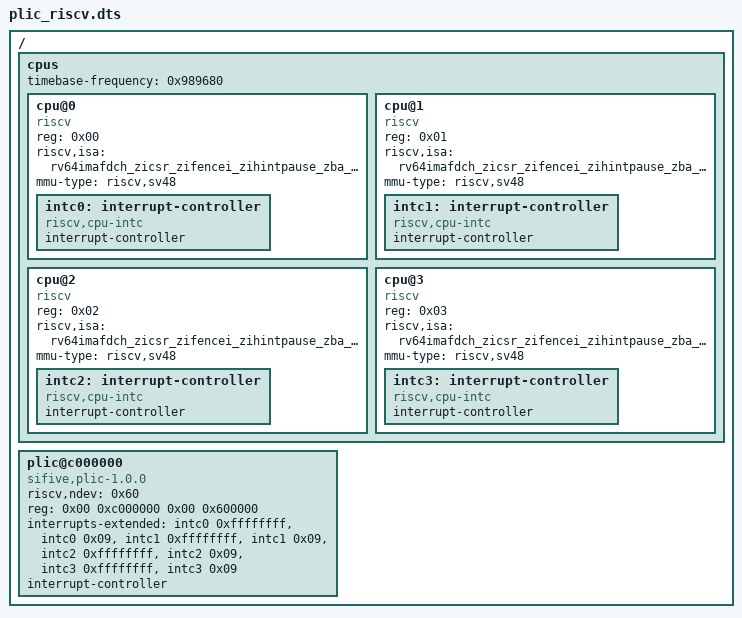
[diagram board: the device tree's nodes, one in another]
// Copyright 2024 The Fuchsia Authors. All rights reserved.
// Use of this source code is governed by a BSD-style license that can be
// found in the LICENSE file.

/dts-v1/;

/ {
    #address-cells = <0x02>;
    #size-cells = <0x02>;

    cpus {
        #address-cells = <0x01>;
        #size-cells = <0x00>;
        timebase-frequency = <0x989680>;

        cpu@0 {
            device_type = "cpu";
            reg = <0x00>;
            compatible = "riscv";
            riscv,isa = "rv64imafdch_zicsr_zifencei_zihintpause_zba_zbb_zbc_zbs_sstc";
            mmu-type = "riscv,sv48";

            intc0: interrupt-controller {
                #address-cells = <0x01>;
                #interrupt-cells = <0x01>;
                interrupt-controller;
                compatible = "riscv,cpu-intc";
            };
        };

        cpu@1 {
            device_type = "cpu";
            reg = <0x01>;
            compatible = "riscv";
            riscv,isa = "rv64imafdch_zicsr_zifencei_zihintpause_zba_zbb_zbc_zbs_sstc";
            mmu-type = "riscv,sv48";

            intc1: interrupt-controller {
                #address-cells = <0x01>;
                #interrupt-cells = <0x01>;
                interrupt-controller;
                compatible = "riscv,cpu-intc";
            };
        };

        cpu@2 {
            device_type = "cpu";
            reg = <0x02>;
            compatible = "riscv";
            riscv,isa = "rv64imafdch_zicsr_zifencei_zihintpause_zba_zbb_zbc_zbs_sstc";
            mmu-type = "riscv,sv48";

            intc2: interrupt-controller {
                #address-cells = <0x01>;
                #interrupt-cells = <0x01>;
                interrupt-controller;
                compatible = "riscv,cpu-intc";
            };
        };

        cpu@3 {
            device_type = "cpu";
            reg = <0x03>;
            compatible = "riscv";
            riscv,isa = "rv64imafdch_zicsr_zifencei_zihintpause_zba_zbb_zbc_zbs_sstc";
            mmu-type = "riscv,sv48";

            intc3: interrupt-controller {
                #address-cells = <0x01>;
                #interrupt-cells = <0x01>;
                interrupt-controller;
                compatible = "riscv,cpu-intc";
            };
        };
    };

    plic@c000000 {
        riscv,ndev = <0x60>;
        reg = <0x00 0xc000000 0x00 0x600000>;
        interrupts-extended = <&intc0 0xffffffff &intc0 0x09 &intc1 0xffffffff &intc1 0x09 &intc2 0xffffffff &intc2 0x09 &intc3 0xffffffff &intc3 0x09>;
        interrupt-controller;
        compatible = "sifive,plic-1.0.0\0riscv,plic0";
        #address-cells = <0x00>;
        #interrupt-cells = <0x01>;
    };
};
